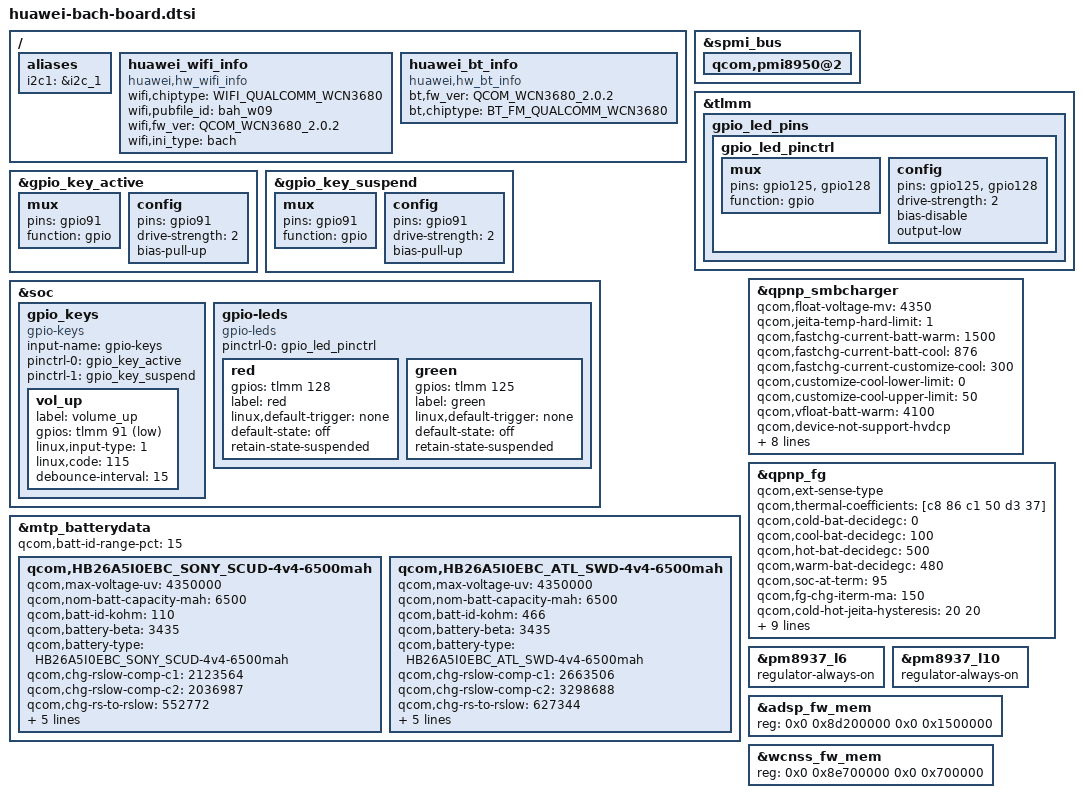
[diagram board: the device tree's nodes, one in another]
/*
 * Huawei Bach board-level overrides carried from the 3.18 vendor tree.
 * Keep this file conservative: only add nodes that either match 4.9 drivers
 * or are harmless metadata needed by vendor userspace.
 */

/ {
	aliases {
		i2c1 = &i2c_1;
	};

	huawei_wifi_info {
		compatible = "huawei,hw_wifi_info";
		status = "ok";
		wifi,chiptype = "WIFI_QUALCOMM_WCN3680";
		wifi,pubfile_id = "bah_w09";
		wifi,fw_ver = "QCOM_WCN3680_2.0.2";
		wifi,ini_type = "bach";
	};

	huawei_bt_info {
		compatible = "huawei,hw_bt_info";
		status = "ok";
		bt,fw_ver = "QCOM_WCN3680_2.0.2";
		bt,chiptype = "BT_FM_QUALCOMM_WCN3680";
	};
};

&spmi_bus {
	qcom,pmi8950@2 {
		/delete-node/ qcom,leds@a100;
	};
};

&tlmm {
	gpio_led_pins {
		gpio_led_pinctrl: gpio_led_pinctrl {
			mux {
				pins = "gpio125", "gpio128";
				function = "gpio";
			};

			config {
				pins = "gpio125", "gpio128";
				drive-strength = <2>;
				bias-disable;
				output-low;
			};
		};
	};
};

&gpio_key_active {
	mux {
		pins = "gpio91";
		function = "gpio";
	};

	config {
		pins = "gpio91";
		drive-strength = <2>;
		bias-pull-up;
	};
};

&gpio_key_suspend {
	mux {
		pins = "gpio91";
		function = "gpio";
	};

	config {
		pins = "gpio91";
		drive-strength = <2>;
		bias-pull-up;
	};
};

&soc {
	/delete-node/ gpio_keys;

	gpio_keys {
		compatible = "gpio-keys";
		input-name = "gpio-keys";
		pinctrl-names = "default", "sleep";
		pinctrl-0 = <&gpio_key_active>;
		pinctrl-1 = <&gpio_key_suspend>;

		vol_up {
			label = "volume_up";
			gpios = <&tlmm 91 0x1>;
			linux,input-type = <1>;
			linux,code = <115>;
			debounce-interval = <15>;
		};
	};

	gpio-leds {
		compatible = "gpio-leds";
		status = "okay";
		pinctrl-names = "default";
		pinctrl-0 = <&gpio_led_pinctrl>;

		red {
			gpios = <&tlmm 128 0>;
			label = "red";
			linux,default-trigger = "none";
			default-state = "off";
			retain-state-suspended;
		};

		green {
			gpios = <&tlmm 125 0>;
			label = "green";
			linux,default-trigger = "none";
			default-state = "off";
			retain-state-suspended;
		};
	};
};

/* Add BAH-W09 battery profiles to existing mtp_batterydata node */
&mtp_batterydata {
	qcom,batt-id-range-pct = <15>;

	qcom,HB26A5I0EBC_SONY_SCUD-4v4-6500mah {
		qcom,max-voltage-uv = <4350000>;
		qcom,nom-batt-capacity-mah = <6500>;
		qcom,batt-id-kohm = <110>;
		qcom,battery-beta = <3435>;
		qcom,battery-type = "HB26A5I0EBC_SONY_SCUD-4v4-6500mah";
		qcom,chg-rslow-comp-c1 = <2123564>;
		qcom,chg-rslow-comp-c2 = <2036987>;
		qcom,chg-rs-to-rslow = <552772>;
		qcom,chg-rslow-comp-thr = <0x99>;
		qcom,checksum = <0xA301>;
		qcom,gui-version = "PMI8950GUI - 2.0.0.16";
		qcom,fg-profile-data = [
			D7 83 36 7C 60 80 E3 75 3F 83 B8 69 B2 78 C1 84
			FA 81 74 99 6A B7 E7 C2 58 11 D6 83 7B 77 F4 7B
			14 75 48 83 4E 68 24 81 C8 8D 11 82 28 9A 61 BD
			D9 CA 55 0E 31 1A 52 58 CE 6E 02 FB D3 0E 61 3F
			5F 38 00 00 85 3F D3 3B 8D 3E 00 00 00 00 00 00
			00 00 00 00 AB 69 B3 68 89 75 E3 80 1E 7C B7 6B
			81 75 AF 7B 0A 7C 86 6B EC 7B 1D C0 0E 6C 59 4E
			4F A0 71 0C 28 00 FF 36 F0 11 30 03 00 00 00 0C
		];
	};

	qcom,HB26A5I0EBC_ATL_SWD-4v4-6500mah {
		qcom,max-voltage-uv = <4350000>;
		qcom,nom-batt-capacity-mah = <6500>;
		qcom,batt-id-kohm = <466>;
		qcom,battery-beta = <3435>;
		qcom,battery-type = "HB26A5I0EBC_ATL_SWD-4v4-6500mah";
		qcom,chg-rslow-comp-c1 = <2663506>;
		qcom,chg-rslow-comp-c2 = <3298688>;
		qcom,chg-rs-to-rslow = <627344>;
		qcom,chg-rslow-comp-thr = <0x99>;
		qcom,checksum = <0xC6A9>;
		qcom,gui-version = "PMI8950GUI - 2.0.0.16";
		qcom,fg-profile-data = [
			AE 82 6B 79 74 7C F2 71 26 83 08 79 B9 85 6A 81
			50 82 E7 93 2C B5 91 C0 7D 11 E5 83 16 7C F1 7B
			A2 74 46 83 CB 71 58 67 15 7D 46 82 8D 99 AB BC
			4E C9 59 0D 82 1A B4 58 CE 6E 02 FB 8B 2D 67 3E
			5F 38 00 00 D9 4C 07 39 AF 31 00 00 00 00 00 00
			00 00 00 00 23 6A FC 68 15 74 2D 88 4D 7C 74 70
			15 3D 66 82 3C 77 D4 6A 75 6D 22 B8 23 4C 62 BC
			5F A0 71 0C 28 00 FF 36 F0 11 30 03 00 00 00 0C
		];
	};
};

&qpnp_smbcharger {
	/delete-property/ qcom,chg-led-sw-controls;
	/delete-property/ qcom,chg-led-support;
	qcom,float-voltage-mv = <4350>;
	qcom,jeita-temp-hard-limit = <1>;
	qcom,fastchg-current-batt-warm = <1500>;
	qcom,fastchg-current-batt-cool = <876>;
	qcom,fastchg-current-customize-cool = <300>;
	qcom,customize-cool-lower-limit = <0>;
	qcom,customize-cool-upper-limit = <50>;
	qcom,vfloat-batt-warm = <4100>;
	qcom,device-not-support-hvdcp;
	qcom,float-voltage-comp = <16>;
	qcom,fastchg-current-ma = <2000>;
	qcom,fastchg-current-comp = <1200>;
	qcom,charge-unknown-battery;
	qcom,iterm-ma = <150>;
	qcom,dcp_icl_ma = <2000>;
	qcom,pad-disable-ibus-detect;
	qcom,charger-batt-capacity-mah = <6660000>;
};

&qpnp_fg {
	qcom,ext-sense-type;
	qcom,thermal-coefficients = [c8 86 c1 50 d3 37];
	qcom,cold-bat-decidegc = <0>;
	qcom,cool-bat-decidegc = <100>;
	qcom,hot-bat-decidegc = <500>;
	qcom,warm-bat-decidegc = <480>;
	qcom,soc-at-term = <95>;
	qcom,fg-chg-iterm-ma = <150>;
	qcom,cold-hot-jeita-hysteresis = <20 20>;
	qcom,fg-iterm-ma = <200>;
	qcom,resume-soc = <99>;
	qcom,resume-soc-raw = <253>;
	qcom,fg-cutoff-voltage-mv = <3250>;
	qcom,bad-battery-detection-enable;
	qcom,hold-soc-while-full;
	qcom,fg-vbat-estimate-diff-mv = <100>;
	qcom,fg-cc-cv-threshold-mv = <4340>;
	qcom,fg-therm-delay-us = <3000>;
};

&pm8937_l6 {
	regulator-always-on;
};

&pm8937_l10 {
	regulator-always-on;
};

/* BAH-W09 needs larger ADSP firmware region (21MB vs default 17MB) */
&adsp_fw_mem {
	reg = <0x0 0x8d200000 0x0 0x1500000>;
};

&wcnss_fw_mem {
	reg = <0x0 0x8e700000 0x0 0x700000>;
};
